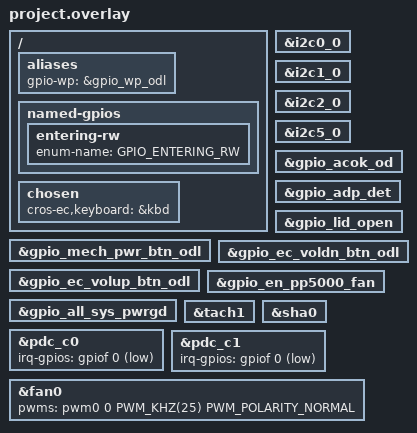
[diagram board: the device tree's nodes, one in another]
/* Copyright 2025 The ChromiumOS Authors
 * Use of this source code is governed by a BSD-style license that can be
 * found in the LICENSE file.
 */

/* ocelot program common DTS includes */

#include <cros/integrated_fwid.dtsi>

/* ocelotrvp-npcx project DTS includes */
#include "generated.dtsi"
#include "../rvp_usba.dtsi"

/*
 * Map I2C buses to common names
 */

i2c_port_pd1: &i2c0_0 {};
i2c_port_pd2: &i2c1_0 {};
i2c_port_charger: &i2c2_0 {};
i2c_port_ish: &i2c5_0 {};

/*
 * Map GPIOs used for interrupts to common names
 */

gpio_acok: &gpio_acok_od {};
gpio_dc_jack_present: &gpio_adp_det {};
gpio_lid: &gpio_lid_open {};
gpio_pwrbtn: &gpio_mech_pwr_btn_odl {};
gpio_voldn: &gpio_ec_voldn_btn_odl {};
gpio_volup: &gpio_ec_volup_btn_odl {};
gpio_fan_control: &gpio_en_pp5000_fan {};
gpio_all_sys_pwr_good: &gpio_all_sys_pwrgd {};

/* Map tachometers to common names */
tach_fan0: &tach1 {};

#include "../rvp_battery.dtsi"
#include "../rvp_i2c.dtsi"
#include "../rvp_interrupts.dtsi"
#include "../rvp_usbc.dtsi"
#include "../rvp_keyboard.dtsi"
#include "../rvp_fans.dtsi"

/* ocelotrvp-npcx overrides follow... */
/ {
	aliases {
		gpio-wp = &gpio_wp_odl;
	};

	named-gpios {
		/* unimplemented GPIOs */
		entering-rw {
			enum-name = "GPIO_ENTERING_RW";
		};
	};

	chosen {
		cros-ec,keyboard = &kbd;
	};
};

&sha0 {
	status = "okay";
};

&pdc_c0 {
	irq-gpios = <&gpiof 0 GPIO_ACTIVE_LOW>;
};

&pdc_c1 {
	irq-gpios = <&gpiof 0 GPIO_ACTIVE_LOW>;
};

&fan0 {
	pwms = <&pwm0 0 PWM_KHZ(25) PWM_POLARITY_NORMAL>;
};

/* Disable nodes for features not yet enabled. */
/delete-node/ &{/named-adc-channels};
